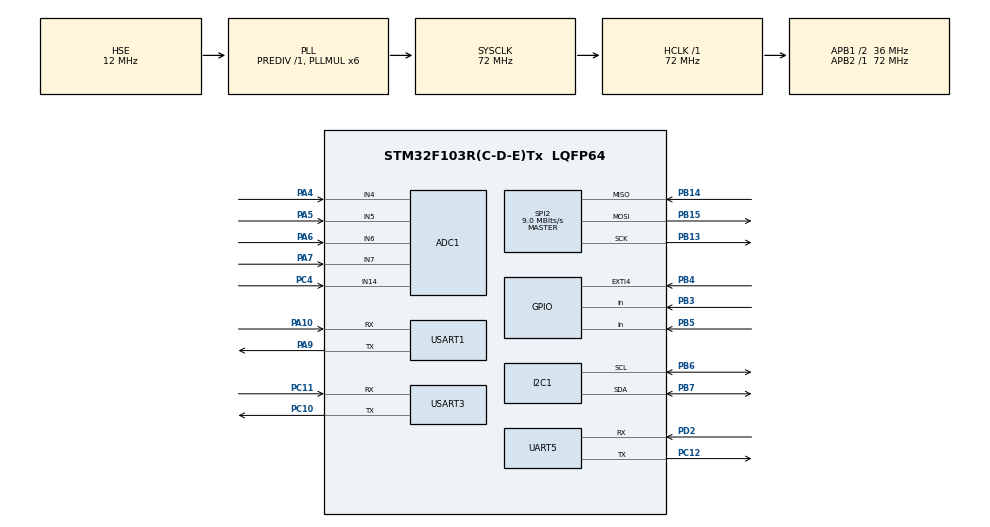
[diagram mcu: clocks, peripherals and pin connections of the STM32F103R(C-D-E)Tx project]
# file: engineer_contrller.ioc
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ADC1.Channel-0\#ChannelRegularConversion=ADC_CHANNEL_4
ADC1.Channel-1\#ChannelRegularConversion=ADC_CHANNEL_5
ADC1.Channel-2\#ChannelRegularConversion=ADC_CHANNEL_6
ADC1.Channel-3\#ChannelRegularConversion=ADC_CHANNEL_7
ADC1.NbrOfConversion=4
ADC1.NbrOfConversionFlag=1
ADC1.Rank-0\#ChannelRegularConversion=1
ADC1.Rank-1\#ChannelRegularConversion=2
ADC1.Rank-2\#ChannelRegularConversion=3
ADC1.Rank-3\#ChannelRegularConversion=4
ADC1.SamplingTime-0\#ChannelRegularConversion=ADC_SAMPLETIME_1CYCLE_5
ADC1.SamplingTime-1\#ChannelRegularConversion=ADC_SAMPLETIME_1CYCLE_5
ADC1.SamplingTime-2\#ChannelRegularConversion=ADC_SAMPLETIME_1CYCLE_5
ADC1.SamplingTime-3\#ChannelRegularConversion=ADC_SAMPLETIME_1CYCLE_5
ADC1.master=1
Dma.ADC1.0.Direction=DMA_PERIPH_TO_MEMORY
Dma.ADC1.0.Instance=DMA1_Channel1
Dma.ADC1.0.MemDataAlignment=DMA_MDATAALIGN_HALFWORD
Dma.ADC1.0.MemInc=DMA_MINC_ENABLE
Dma.ADC1.0.Mode=DMA_CIRCULAR
Dma.ADC1.0.PeriphDataAlignment=DMA_PDATAALIGN_HALFWORD
Dma.ADC1.0.PeriphInc=DMA_PINC_DISABLE
Dma.ADC1.0.Priority=DMA_PRIORITY_LOW
Dma.Request0=ADC1
Dma.Request1=USART3_TX
Dma.USART3_TX.1.Direction=DMA_MEMORY_TO_PERIPH
Dma.USART3_TX.1.Instance=DMA1_Channel2
Dma.USART3_TX.1.MemDataAlignment=DMA_MDATAALIGN_BYTE
Dma.USART3_TX.1.MemInc=DMA_MINC_ENABLE
Dma.USART3_TX.1.Mode=DMA_NORMAL
Dma.USART3_TX.1.PeriphDataAlignment=DMA_PDATAALIGN_BYTE
Dma.USART3_TX.1.PeriphInc=DMA_PINC_DISABLE
Dma.USART3_TX.1.Priority=DMA_PRIORITY_LOW
I2C1.I2C_Mode=I2C_Fast
Mcu.Family=STM32F1
Mcu.Name=STM32F103R(C-D-E)Tx
Mcu.Package=LQFP64
NVIC.ADC1_2_IRQn=true\:0\:0\:false\:false\:true\:true\:true\:true
NVIC.DMA1_Channel1_IRQn=true\:0\:0\:false\:false\:true\:false\:true\:true
NVIC.DMA1_Channel2_IRQn=true\:0\:0\:false\:false\:true\:false\:true\:true
NVIC.EXTI4_IRQn=true\:0\:0\:false\:false\:true\:true\:true\:true
NVIC.PriorityGroup=NVIC_PRIORITYGROUP_4
NVIC.TIM2_IRQn=true\:0\:0\:false\:false\:true\:true\:true\:true
NVIC.USART3_IRQn=true\:0\:0\:false\:false\:true\:true\:true\:true
PA10.Mode=Asynchronous
PA10.Signal=USART1_RX
PA13.Mode=Serial_Wire
PA13.Signal=SYS_JTMS-SWDIO
PA14.Mode=Serial_Wire
PA14.Signal=SYS_JTCK-SWCLK
PA4.Signal=ADCx_IN4
PA5.Signal=ADCx_IN5
PA6.Signal=ADCx_IN6
PA7.Signal=ADCx_IN7
PA9.Mode=Asynchronous
PA9.Signal=USART1_TX
PB1.Signal=ADCx_IN9
PB13.Mode=Full_Duplex_Master
PB13.Signal=SPI2_SCK
PB14.Mode=Full_Duplex_Master
PB14.Signal=SPI2_MISO
PB15.Mode=Full_Duplex_Master
PB15.Signal=SPI2_MOSI
PB3.Signal=GPIO_Input
PB4.Signal=GPXTI4
PB5.Signal=GPIO_Input
PB6.Mode=I2C
PB6.Signal=I2C1_SCL
PB7.Mode=I2C
PB7.Signal=I2C1_SDA
PC10.Mode=Asynchronous
PC10.Signal=USART3_TX
PC11.Mode=Asynchronous
PC11.Signal=USART3_RX
PC12.Mode=Asynchronous
PC12.Signal=UART5_TX
PC4.Signal=ADCx_IN14
PD0-OSC_IN.Mode=HSE-External-Oscillator
PD0-OSC_IN.Signal=RCC_OSC_IN
PD1-OSC_OUT.Mode=HSE-External-Oscillator
PD1-OSC_OUT.Signal=RCC_OSC_OUT
PD2.Mode=Asynchronous
PD2.Signal=UART5_RX
ProjectManager.HeapSize=0x200
ProjectManager.StackSize=0x400
ProjectManager.TargetToolchain=MDK-ARM V5.32
RCC.ADCPresc=RCC_ADCPCLK2_DIV6
RCC.AHBFreq_Value=72000000
RCC.APB1CLKDivider=RCC_HCLK_DIV2
RCC.APB1Freq_Value=36000000
RCC.APB1TimFreq_Value=72000000
RCC.APB2Freq_Value=72000000
RCC.APB2TimFreq_Value=72000000
RCC.HCLKFreq_Value=72000000
RCC.HSE_VALUE=12000000
RCC.PLLMUL=RCC_PLL_MUL6
RCC.PLLSourceVirtual=RCC_PLLSOURCE_HSE
RCC.SYSCLKFreq_VALUE=72000000
RCC.SYSCLKSource=RCC_SYSCLKSOURCE_PLLCLK
RCC.USBFreq_Value=72000000
SH.ADCx_IN14.0=ADC1_IN14,IN14
SH.ADCx_IN4.0=ADC1_IN4,IN4
SH.ADCx_IN5.0=ADC1_IN5,IN5
SH.ADCx_IN6.0=ADC1_IN6,IN6
SH.ADCx_IN7.0=ADC1_IN7,IN7
SH.ADCx_IN9.0=ADC2_IN9
SPI2.BaudRatePrescaler=SPI_BAUDRATEPRESCALER_4
SPI2.CLKPhase=SPI_PHASE_2EDGE
SPI2.CalculateBaudRate=9.0 MBits/s
SPI2.Direction=SPI_DIRECTION_2LINES
SPI2.Mode=SPI_MODE_MASTER
SPI2.VirtualType=VM_MASTER
TIM2.Period=999
TIM2.Prescaler=71
UART5.VirtualMode=Asynchronous
USART1.VirtualMode=VM_ASYNC
USART3.VirtualMode=VM_ASYNC
VP_TIM2_VS_ClockSourceINT.Mode=Internal
board=custom

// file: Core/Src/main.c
/* USER CODE BEGIN Header */
/**
  ******************************************************************************
  * @file           : main.c
  * @brief          : Main program body
  ******************************************************************************
  * @attention
  *
  * Copyright (c) 2025 STMicroelectronics.
  * All rights reserved.
  *
  * This software is licensed under terms that can be found in the LICENSE file
  * in the root directory of this software component.
  * If no LICENSE file comes with this software, it is provided AS-IS.
  *
  ******************************************************************************
  */
/* USER CODE END Header */
#include "main.h"
#include "adc.h"
#include "dma.h"
#include "i2c.h"
#include "spi.h"
#include "tim.h"
#include "usart.h"
#include "gpio.h"

/* USER CODE BEGIN Includes */
#include "bsp_tim.h"
#include "bsp_adc.h"
#include "ws2812.h"
#include "joint.h"
#include "potentiometer.h"
#include "oled.h"
#include "font.h"
/* USER CODE END Includes */

void SystemClock_Config(void);

int main(void)
{

  /* MCU Configuration--------------------------------------------------------*/

  /* Reset of all peripherals, Initializes the Flash interface and the Systick. */
  HAL_Init();

  /* Configure the system clock */
  SystemClock_Config();

  /* Initialize all configured peripherals */
  MX_GPIO_Init();
  MX_DMA_Init();
  MX_ADC1_Init();
  MX_TIM2_Init();
  MX_SPI2_Init();
  MX_USART3_UART_Init();
  MX_UART5_Init();
  MX_USART1_UART_Init();
  MX_I2C1_Init();
  /* USER CODE BEGIN 2 */
  bsp_adc_init();
  joint_init();
  OLED_Init();

  bsp_tim_init();

  /* USER CODE END 2 */

  /* Infinite loop */
  /* USER CODE BEGIN WHILE */

  while (1)
  {
    HAL_Delay(5);
    /* USER CODE END WHILE */

  }
}

void SystemClock_Config(void)
{
  RCC_OscInitTypeDef RCC_OscInitStruct = {0};
  RCC_ClkInitTypeDef RCC_ClkInitStruct = {0};
  RCC_PeriphCLKInitTypeDef PeriphClkInit = {0};

  /** Initializes the RCC Oscillators according to the specified parameters
  * in the RCC_OscInitTypeDef structure.
  */
  RCC_OscInitStruct.OscillatorType = RCC_OSCILLATORTYPE_HSE;
  RCC_OscInitStruct.HSEState = RCC_HSE_ON;
  RCC_OscInitStruct.HSEPredivValue = RCC_HSE_PREDIV_DIV1;
  RCC_OscInitStruct.HSIState = RCC_HSI_ON;
  RCC_OscInitStruct.PLL.PLLState = RCC_PLL_ON;
  RCC_OscInitStruct.PLL.PLLSource = RCC_PLLSOURCE_HSE;
  RCC_OscInitStruct.PLL.PLLMUL = RCC_PLL_MUL6;
  if (HAL_RCC_OscConfig(&RCC_OscInitStruct) != HAL_OK)
  {
    Error_Handler();
  }

  /** Initializes the CPU, AHB and APB buses clocks
  */
  RCC_ClkInitStruct.ClockType = RCC_CLOCKTYPE_HCLK|RCC_CLOCKTYPE_SYSCLK
                              |RCC_CLOCKTYPE_PCLK1|RCC_CLOCKTYPE_PCLK2;
  RCC_ClkInitStruct.SYSCLKSource = RCC_SYSCLKSOURCE_PLLCLK;
  RCC_ClkInitStruct.AHBCLKDivider = RCC_SYSCLK_DIV1;
  RCC_ClkInitStruct.APB1CLKDivider = RCC_HCLK_DIV2;
  RCC_ClkInitStruct.APB2CLKDivider = RCC_HCLK_DIV1;

  if (HAL_RCC_ClockConfig(&RCC_ClkInitStruct, FLASH_LATENCY_2) != HAL_OK)
  {
    Error_Handler();
  }
  PeriphClkInit.PeriphClockSelection = RCC_PERIPHCLK_ADC;
  PeriphClkInit.AdcClockSelection = RCC_ADCPCLK2_DIV6;
  if (HAL_RCCEx_PeriphCLKConfig(&PeriphClkInit) != HAL_OK)
  {
    Error_Handler();
  }
}

void Error_Handler(void)
{
  __disable_irq();
  while (1)
  {
  }
}
